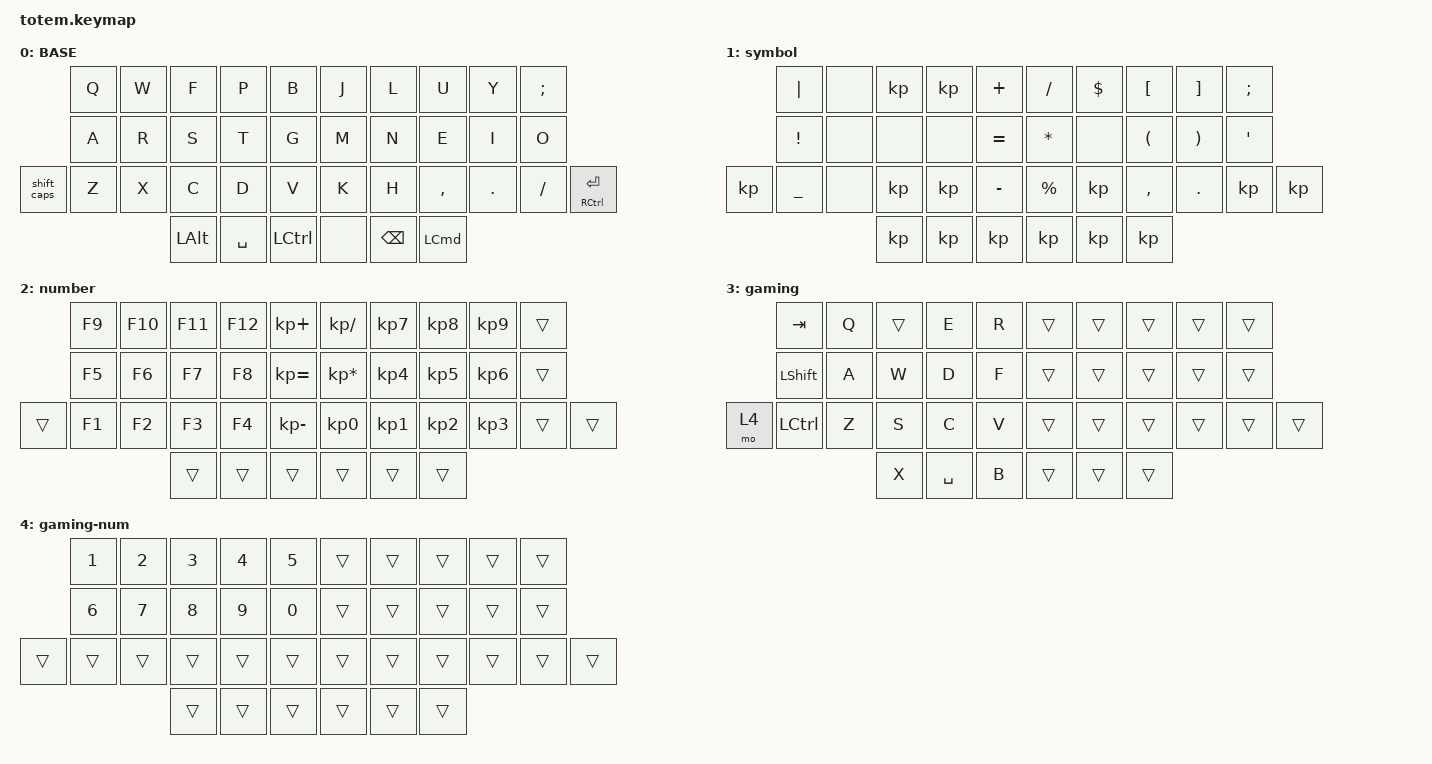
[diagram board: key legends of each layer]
//
//                                                        ▀▀▀▀▀     ▀▀▀▀▀          ▀▀█▀▀
//                                                        ▄▀▀▀▄  ▄  ▄▀▀▀▄  ▄  ▄▀▀▀▄  █  ▄▀▀▀▄
//                                                        █   █  █  █   █  █  █   █  █  █   █
//                                                         ▀▀▀   █   ▀▀▀   █   ▀▀▀   ▀   ▀▀▀
//                                                               █      ▄▄▄█▄▄▄    █   █  
//                                                               ▀      █  █  █     █▄█
//                                                             ▀▀▀▀▀    █  █  █      ▀
//                                                                      ▀  ▀  ▀
//
// ▄▄▄▄▄▄▄▄▄▄▄▄▄▄▄▄▄▄▄▄▄▄▄▄▄▄▄▄▄▄▄▄▄▄▄▄▄▄▄▄▄▄▄▄▄▄▄▄▄▄▄▄▄▄▄▄▄▄▄▄▄▄▄▄▄▄▄▄▄▄▄▄▄▄▄▄▄▄▄▄▄▄▄▄▄▄▄▄▄▄▄▄▄▄▄▄▄▄▄▄▄▄▄▄▄▄▄▄▄▄▄▄▄▄▄▄▄▄▄▄▄▄▄▄▄▄▄▄▄▄▄▄▄▄▄▄▄▄▄▄▄▄▄▄▄▄▄▄▄

#include <behaviors.dtsi>
#include <dt-bindings/zmk/keys.h>

#define BASE 0
#define NAV  1
#define SYM  2
#define ADJ  3
#define TVP1 4
#define TVP2 5

&mt {
    quick-tap-ms = <100>;
    global-quick-tap;
    flavor = "tap-preferred";
    tapping-term-ms = <170>;
};

/ {
    combos {
        compatible = "zmk,combos";

        combo_esc {
            timeout-ms = <50>;
            key-positions = <1 2>;
            bindings = <&kp ESC>;
        };

        gaming-mode {
            bindings = <&tog 3>;
            key-positions = <1 10 12 24>;
        };

        combo_del {
            bindings = <&kp DELETE>;
            key-positions = <8 7>;
        };

        combo_tab {
            bindings = <&kp TAB>;
            key-positions = <0 1>;
        };

        combo_func_call_brackets {
            bindings = <&func_call_brackets>;
            key-positions = <17 18 9>;
            layers = <1>;
        };

        combo_func_define_brackets {
            bindings = <&func_define_brackets>;
            key-positions = <17 18 20>;
            layers = <1>;
        };
    };

    macros {
        gif: gif {
            label = "giphy";
            compatible = "zmk,behavior-macro";
            #binding-cells = <0>;
            bindings =
                <&macro_press>,
                <&kp LSHFT>,
                <&macro_tap>,
                <&kp N2>,
                <&macro_release>,
                <&kp LSHFT>,
                <&macro_tap>,
                <&kp G &kp I &kp F>;
        };

        func_call_brackets: func_call_end {
            compatible = "zmk,behavior-macro";
            #binding-cells = <0>;
            bindings = <&kp LEFT_PARENTHESIS &kp RIGHT_PARENTHESIS &kp SEMICOLON>;
            label = "FUNC_CALL_END";
        };

        func_define_brackets: func_define_brackets {
            compatible = "zmk,behavior-macro";
            #binding-cells = <0>;
            bindings = <&kp LEFT_PARENTHESIS &kp RIGHT_PARENTHESIS &kp SPACE &kp LEFT_BRACE &kp RIGHT_BRACE &kp LEFT &kp ENTER>;
            label = "FUNC_DEFINE_BRACKETS";
        };
    };

    behaviors {
        shift_caps: shift_caps {
            compatible = "zmk,behavior-tap-dance";
            label = "SHIFT_CAPS";
            #binding-cells = <0>;
            bindings = <&kp LEFT_SHIFT>, <&kp CAPSLOCK>;
        };
    };

    keymap {
        compatible = "zmk,keymap";

        // ▄▄▄▄▄▄▄▄▄▄▄▄▄▄▄▄▄▄▄▄▄▄▄▄▄▄▄▄▄▄▄▄▄▄▄▄▄▄▄▄▄▄▄▄▄▄▄▄▄▄▄▄▄▄▄▄▄▄▄▄▄▄▄▄▄▄▄▄▄▄▄▄▄▄▄▄▄▄▄▄▄▄▄▄▄▄▄▄▄▄▄▄▄▄▄▄▄▄▄▄▄▄▄▄▄▄▄▄▄▄▄▄▄▄▄▄▄▄▄▄▄▄▄▄▄▄▄▄▄▄▄▄▄▄▄▄▄▄▄▄▄▄▄▄▄▄▄▄▄

        base {
            // ┏━━━━━━━━━━━━━━━━━━━━━━━━━━━━━━━━━━━━━━━┓

            label = "BASE";

            // ┗━━━━━━━━━━━━━━━━━━━━━━━━━━━━━━━━━━━━━━━┛
            //             ┏━━━━━━━━━━━┳━━━━━━━━━━━┳━━━━━━━━━━━┳━━━━━━━━━━━┳━━━━━━━━━━━┓   ┏━━━━━━━━━━━┳━━━━━━━━━━━┳━━━━━━━━━━━┳━━━━━━━━━━━┳━━━━━━━━━━━┓
            //             ┃     Q     ┃     W     ┃     F     ┃     P     ┃     G     ┃   ┃     J     ┃     L     ┃     U     ┃     Y     ┃     ;     ┃
            //             ┣━━━━━━━━━━━╋━━━━━━━━━━━╋━━━━━━━━━━━╋━━━━━━━━━━━╋━━━━━━━━━━━┫   ┣━━━━━━━━━━━╋━━━━━━━━━━━╋━━━━━━━━━━━╋━━━━━━━━━━━╋━━━━━━━━━━━┫
            //             ┃     A     ┃     R     ┃     S     ┃     T     ┃     D     ┃   ┃     H     ┃     N     ┃     E     ┃     I     ┃     O     ┃
            // ┏━━━━━━━━━━━╋━━━━━━━━━━━╋━━━━━━━━━━━╋━━━━━━━━━━━╋━━━━━━━━━━━╋━━━━━━━━━━━┫   ┣━━━━━━━━━━━╋━━━━━━━━━━━╋━━━━━━━━━━━╋━━━━━━━━━━━╋━━━━━━━━━━━╋━━━━━━━━━━━┓
            // ┃     Q     ┃     Z     ┃     X     ┃     C     ┃     V     ┃     B     ┃   ┃     K     ┃     M     ┃     ,     ┃     .     ┃     /     ┃     \     ┃
            // ┗━━━━━━━━━━━┻━━━━━━━━━━━┻━━━━━━━━━━━╋━━━━━━━━━━━╋━━━━━━━━━━━╋━━━━━━━━━━━┫   ┣━━━━━━━━━━━╋━━━━━━━━━━━╋━━━━━━━━━━━╋━━━━━━━━━━━┻━━━━━━━━━━━┻━━━━━━━━━━━┛
            //                                     ┃    DEL    ┃    TAB    ┃    SPC    ┃   ┃   ENTER   ┃           ┃   BSPC    ┃
            //                                     ┗━━━━━━━━━━━┻━━━━━━━━━━━┻━━━━━━━━━━━┛   ┗━━━━━━━━━━━┻━━━━━━━━━━━┻━━━━━━━━━━━┛

            bindings = <
             &kp Q  &kp W  &kp F         &kp P      &kp B        &kp J  &kp L          &kp U             &kp Y    &kp SEMI
             &kp A  &kp R  &kp S         &kp T      &kp G        &kp M  &kp N          &kp E             &kp I    &kp O
&shift_caps  &kp Z  &kp X  &kp C         &kp D      &kp V        &kp K  &kp H          &kp COMMA         &kp DOT  &kp FSLH  &mt RCTRL ENTER
                           &kp LEFT_ALT  &kp SPACE  &kp LCTRL    &none  &kp BACKSPACE  &kp LEFT_COMMAND
            >;
        };

        // ▄▄▄▄▄▄▄▄▄▄▄▄▄▄▄▄▄▄▄▄▄▄▄▄▄▄▄▄▄▄▄▄▄▄▄▄▄▄▄▄▄▄▄▄▄▄▄▄▄▄▄▄▄▄▄▄▄▄▄▄▄▄▄▄▄▄▄▄▄▄▄▄▄▄▄▄▄▄▄▄▄▄▄▄▄▄▄▄▄▄▄▄▄▄▄▄▄▄▄▄▄▄▄▄▄▄▄▄▄▄▄▄▄▄▄▄▄▄▄▄▄▄▄▄▄▄▄▄▄▄▄▄▄▄▄▄▄▄▄▄▄▄▄▄▄▄▄▄▄
        // ▄▄▄▄▄▄▄▄▄▄▄▄▄▄▄▄▄▄▄▄▄▄▄▄▄▄▄▄▄▄▄▄▄▄▄▄▄▄▄▄▄▄▄▄▄▄▄▄▄▄▄▄▄▄▄▄▄▄▄▄▄▄▄▄▄▄▄▄▄▄▄▄▄▄▄▄▄▄▄▄▄▄▄▄▄▄▄▄▄▄▄▄▄▄▄▄▄▄▄▄▄▄▄▄▄▄▄▄▄▄▄▄▄▄▄▄▄▄▄▄▄▄▄▄▄▄▄▄▄▄▄▄▄▄▄▄▄▄▄▄▄▄▄▄▄▄▄▄▄
        // ▄▄▄▄▄▄▄▄▄▄▄▄▄▄▄▄▄▄▄▄▄▄▄▄▄▄▄▄▄▄▄▄▄▄▄▄▄▄▄▄▄▄▄▄▄▄▄▄▄▄▄▄▄▄▄▄▄▄▄▄▄▄▄▄▄▄▄▄▄▄▄▄▄▄▄▄▄▄▄▄▄▄▄▄▄▄▄▄▄▄▄▄▄▄▄▄▄▄▄▄▄▄▄▄▄▄▄▄▄▄▄▄▄▄▄▄▄▄▄▄▄▄▄▄▄▄▄▄▄▄▄▄▄▄▄▄▄▄▄▄▄▄▄▄▄▄▄▄▄
        // ▄▄▄▄▄▄▄▄▄▄▄▄▄▄▄▄▄▄▄▄▄▄▄▄▄▄▄▄▄▄▄▄▄▄▄▄▄▄▄▄▄▄▄▄▄▄▄▄▄▄▄▄▄▄▄▄▄▄▄▄▄▄▄▄▄▄▄▄▄▄▄▄▄▄▄▄▄▄▄▄▄▄▄▄▄▄▄▄▄▄▄▄▄▄▄▄▄▄▄▄▄▄▄▄▄▄▄▄▄▄▄▄▄▄▄▄▄▄▄▄▄▄▄▄▄▄▄▄▄▄▄▄▄▄▄▄▄▄▄▄▄▄▄▄▄▄▄▄▄
        // ▄▄▄▄▄▄▄▄▄▄▄▄▄▄▄▄▄▄▄▄▄▄▄▄▄▄▄▄▄▄▄▄▄▄▄▄▄▄▄▄▄▄▄▄▄▄▄▄▄▄▄▄▄▄▄▄▄▄▄▄▄▄▄▄▄▄▄▄▄▄▄▄▄▄▄▄▄▄▄▄▄▄▄▄▄▄▄▄▄▄▄▄▄▄▄▄▄▄▄▄▄▄▄▄▄▄▄▄▄▄▄▄▄▄▄▄▄▄▄▄▄▄▄▄▄▄▄▄▄▄▄▄▄▄▄▄▄▄▄▄▄▄▄▄▄▄▄▄▄

        symbol {
            bindings = <
     &kp PIPE         &none  &kp    &kp    &kp PLUS     &kp SLASH    &kp DOLLAR  &kp LEFT_BRACKET      &kp RIGHT_BRACKET      &kp SEMICOLON
     &kp EXCLAMATION  &none  &none  &none  &kp EQUAL    &kp ASTRK    &none       &kp LEFT_PARENTHESIS  &kp RIGHT_PARENTHESIS  &kp APOS
&kp  &kp UNDERSCORE   &none  &kp    &kp    &kp MINUS    &kp PERCENT  &kp         &kp COMMA             &kp PERIOD             &kp            &kp
                             &kp    &kp    &kp          &kp          &kp         &kp
            >;
        };

        number {
            bindings = <
        &kp F9  &kp F10  &kp F11  &kp F12  &kp KP_PLUS     &kp KP_DIVIDE    &kp KP_NUMBER_7  &kp KP_NUMBER_8  &kp KP_NUMBER_9  &trans
        &kp F5  &kp F6   &kp F7   &kp F8   &kp KP_EQUAL    &kp KP_ASTERISK  &kp KP_NUMBER_4  &kp KP_NUMBER_5  &kp KP_NUMBER_6  &trans
&trans  &kp F1  &kp F2   &kp F3   &kp F4   &kp KP_MINUS    &kp KP_N0        &kp KP_NUMBER_1  &kp KP_NUMBER_2  &kp KP_NUMBER_3  &trans  &trans
                         &trans   &trans   &trans          &trans           &trans           &trans
            >;
        };

        gaming {
            bindings = <
       &kp TAB    &kp Q  &trans  &kp E      &kp R    &trans  &trans  &trans  &trans  &trans
       &kp LSHFT  &kp A  &kp W   &kp D      &kp F    &trans  &trans  &trans  &trans  &trans
&mo 4  &kp LCTRL  &kp Z  &kp S   &kp C      &kp V    &trans  &trans  &trans  &trans  &trans  &trans
                         &kp X   &kp SPACE  &kp B    &trans  &trans  &trans
            >;
        };

        gaming-num {
            bindings = <
        &kp N1  &kp N2  &kp N3  &kp N4  &kp N5    &trans  &trans  &trans  &trans  &trans
        &kp N6  &kp N7  &kp N8  &kp N9  &kp N0    &trans  &trans  &trans  &trans  &trans
&trans  &trans  &trans  &trans  &trans  &trans    &trans  &trans  &trans  &trans  &trans  &trans
                        &trans  &trans  &trans    &trans  &trans  &trans
            >;
        };
    };
};
